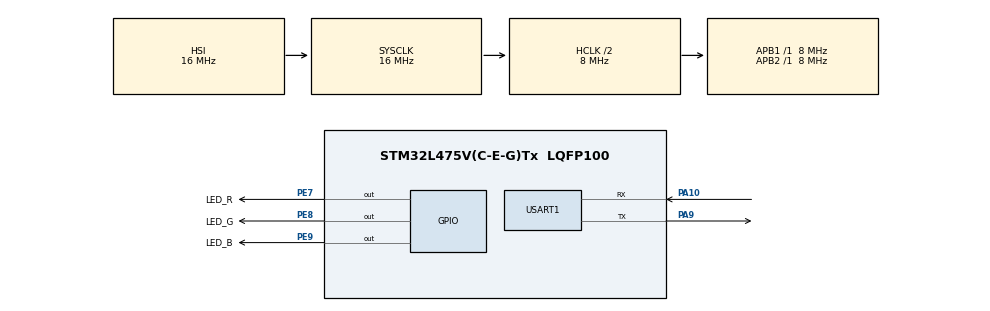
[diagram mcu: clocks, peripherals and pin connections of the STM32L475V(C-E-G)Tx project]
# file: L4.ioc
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Mcu.Family=STM32L4
Mcu.Name=STM32L475V(C-E-G)Tx
Mcu.Package=LQFP100
NVIC.PriorityGroup=NVIC_PRIORITYGROUP_4
NVIC.TIM3_IRQn=true\:0\:0\:false\:false\:true\:true\:true\:true
NVIC.USART1_IRQn=true\:0\:0\:false\:false\:true\:true\:true\:true
PA10.Mode=Asynchronous
PA10.Signal=USART1_RX
PA13\ (JTMS-SWDIO).Mode=Serial_Wire
PA13\ (JTMS-SWDIO).Signal=SYS_JTMS-SWDIO
PA14\ (JTCK-SWCLK).Mode=Serial_Wire
PA14\ (JTCK-SWCLK).Signal=SYS_JTCK-SWCLK
PA9.Mode=Asynchronous
PA9.Signal=USART1_TX
PE7.GPIO_Label=LED_R
PE7.GPIO_PuPd=GPIO_PULLUP
PE7.PinState=GPIO_PIN_SET
PE7.Signal=GPIO_Output
PE8.GPIO_Label=LED_G
PE8.GPIO_PuPd=GPIO_PULLUP
PE8.PinState=GPIO_PIN_SET
PE8.Signal=GPIO_Output
PE9.GPIO_Label=LED_B
PE9.GPIO_PuPd=GPIO_PULLUP
PE9.PinState=GPIO_PIN_SET
PE9.Signal=GPIO_Output
ProjectManager.HeapSize=0x200
ProjectManager.StackSize=0x400
ProjectManager.TargetToolchain=CMake
RCC.ADCFreq_Value=64000000
RCC.AHBCLKDivider=RCC_SYSCLK_DIV2
RCC.AHBFreq_Value=8000000
RCC.APB1Freq_Value=8000000
RCC.APB1TimFreq_Value=8000000
RCC.APB2Freq_Value=8000000
RCC.APB2TimFreq_Value=8000000
RCC.CortexFreq_Value=8000000
RCC.HCLKFreq_Value=8000000
RCC.HSE_VALUE=16000000
RCC.HSI_VALUE=16000000
RCC.LSE_VALUE=32768
RCC.MSIClockRange=RCC_MSIRANGE_7
RCC.MSI_VALUE=8000000
RCC.PLLR=RCC_PLLR_DIV8
RCC.PLLSourceVirtual=RCC_PLLSOURCE_HSI
RCC.SYSCLKFreq_VALUE=16000000
RCC.SYSCLKSource=RCC_SYSCLKSOURCE_HSI
RCC.USBFreq_Value=64000000
RCC.VCOOutputFreq_Value=128000000
TIM3.Period=7999
TIM4.Period=65535
TIM4.Prescaler=0
USART1.VirtualMode-Asynchronous=VM_ASYNC
VP_TIM3_VS_ClockSourceINT.Mode=Internal
VP_TIM4_VS_ClockSourceINT.Mode=Internal
board=custom

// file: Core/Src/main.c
/* USER CODE BEGIN Header */
/**
 ******************************************************************************
 * @file           : main.c
 * @brief          : Main program body
 ******************************************************************************
 * @attention
 *
 * Copyright (c) 2024 STMicroelectronics.
 * All rights reserved.
 *
 * This software is licensed under terms that can be found in the LICENSE file
 * in the root directory of this software component.
 * If no LICENSE file comes with this software, it is provided AS-IS.
 *
 ******************************************************************************
 */
/* USER CODE END Header */
#include "main.h"
#include "gpio.h"
#include "tim.h"
#include "usart.h"

/* USER CODE BEGIN Includes */
#include "icm20608.h"
#include "led.h"
/* USER CODE END Includes */

void SystemClock_Config(void);

int main(void) {

  /* MCU Configuration--------------------------------------------------------*/

  /* Reset of all peripherals, Initializes the Flash interface and the Systick.
   */
  HAL_Init();

  /* Configure the system clock */
  SystemClock_Config();

  /* Initialize all configured peripherals */
  MX_GPIO_Init();
  MX_USART1_UART_Init();
  MX_TIM3_Init();
  MX_TIM4_Init();
  /* USER CODE BEGIN 2 */
  ICM20608_Init();
  /* USER CODE END 2 */

  /* Infinite loop */
  /* USER CODE BEGIN WHILE */
  __HAL_TIM_CLEAR_IT(&htim3, TIM_IT_UPDATE);
  HAL_TIM_Base_Start_IT(&htim3);
  while (1) {
    /* USER CODE END WHILE */

  }
}

void SystemClock_Config(void) {
  RCC_OscInitTypeDef RCC_OscInitStruct = {0};
  RCC_ClkInitTypeDef RCC_ClkInitStruct = {0};

  /** Configure the main internal regulator output voltage
   */
  if (HAL_PWREx_ControlVoltageScaling(PWR_REGULATOR_VOLTAGE_SCALE1) != HAL_OK) {
    Error_Handler();
  }

  /** Initializes the RCC Oscillators according to the specified parameters
   * in the RCC_OscInitTypeDef structure.
   */
  RCC_OscInitStruct.OscillatorType = RCC_OSCILLATORTYPE_HSI;
  RCC_OscInitStruct.HSIState = RCC_HSI_ON;
  RCC_OscInitStruct.HSICalibrationValue = RCC_HSICALIBRATION_DEFAULT;
  RCC_OscInitStruct.PLL.PLLState = RCC_PLL_NONE;
  if (HAL_RCC_OscConfig(&RCC_OscInitStruct) != HAL_OK) {
    Error_Handler();
  }

  /** Initializes the CPU, AHB and APB buses clocks
   */
  RCC_ClkInitStruct.ClockType = RCC_CLOCKTYPE_HCLK | RCC_CLOCKTYPE_SYSCLK |
                                RCC_CLOCKTYPE_PCLK1 | RCC_CLOCKTYPE_PCLK2;
  RCC_ClkInitStruct.SYSCLKSource = RCC_SYSCLKSOURCE_HSI;
  RCC_ClkInitStruct.AHBCLKDivider = RCC_SYSCLK_DIV2;
  RCC_ClkInitStruct.APB1CLKDivider = RCC_HCLK_DIV1;
  RCC_ClkInitStruct.APB2CLKDivider = RCC_HCLK_DIV1;

  if (HAL_RCC_ClockConfig(&RCC_ClkInitStruct, FLASH_LATENCY_0) != HAL_OK) {
    Error_Handler();
  }
}

void Error_Handler(void) {
  /* USER CODE BEGIN Error_Handler_Debug */
  printf("sad, an error has been handled!\n");
  /* User can add his own implementation to report the HAL error return state */
  __disable_irq();
  while (1) {
  }
  /* USER CODE END Error_Handler_Debug */
}

#ifdef USE_FULL_ASSERT
/**
 * @brief  Reports the name of the source file and the source line number
 *         where the assert_param error has occurred.
 * @param  file: pointer to the source file name
 * @param  line: assert_param error line source number
 * @retval None
 */
void assert_failed(uint8_t* file, uint32_t line) {
  /* USER CODE BEGIN 6 */
  /* User can add his own implementation to report the file name and line
     number, ex: printf("Wrong parameters value: file %s on line %d\r\n", file,
     line) */
  /* USER CODE END 6 */
}
#endif /* USE_FULL_ASSERT */
